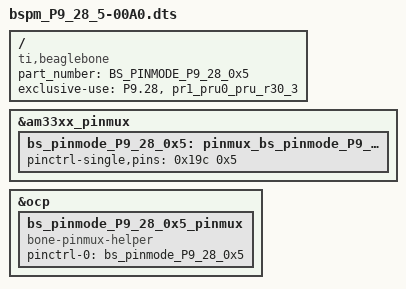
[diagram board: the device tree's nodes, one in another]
/*
 * This is a template-generated file from BoneScript
 */

/dts-v1/;
/plugin/;

/{
    compatible = "ti,beaglebone", "ti,beaglebone-black";
    part_number = "BS_PINMODE_P9_28_0x5";

    exclusive-use =
        "P9.28",
        "pr1_pru0_pru_r30_3";

    fragment@0 {
        target = <&am33xx_pinmux>;
        __overlay__ {
            bs_pinmode_P9_28_0x5: pinmux_bs_pinmode_P9_28_0x5 {
                pinctrl-single,pins = <0x19c 0x5>;
            };
        };
    };

    fragment@1 {
        target = <&ocp>;
        __overlay__ {
            bs_pinmode_P9_28_0x5_pinmux {
                compatible = "bone-pinmux-helper";
                status = "okay";
                pinctrl-names = "default";
                pinctrl-0 = <&bs_pinmode_P9_28_0x5>;
            };
        };
    };
};


